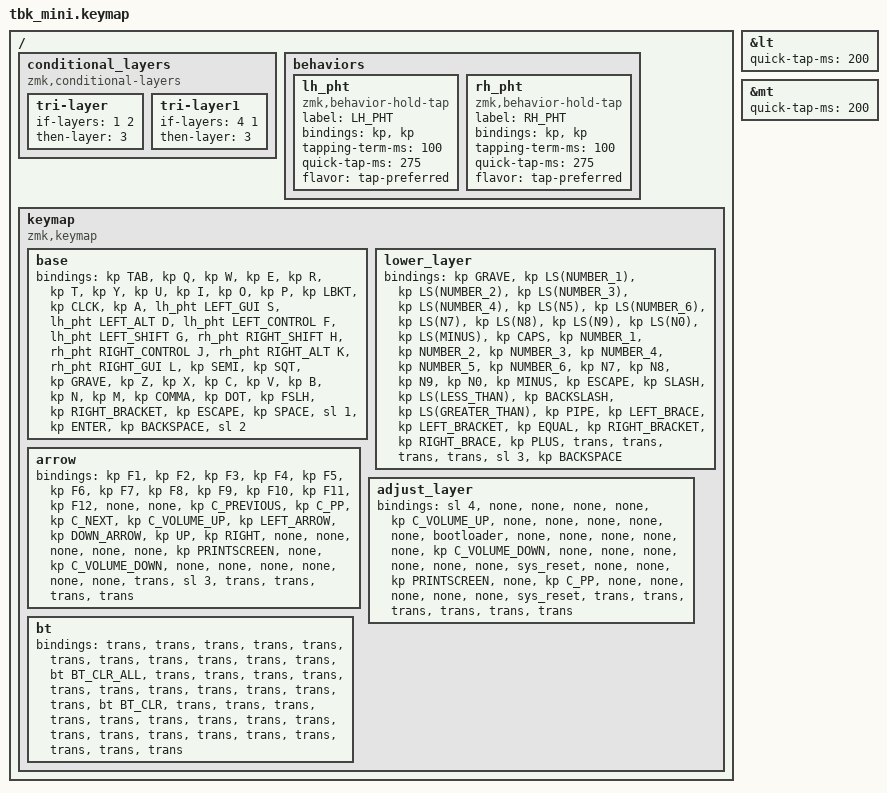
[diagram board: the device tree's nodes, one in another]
/*
 * Copyright (c) 2020 The ZMK Contributors
 *
 * SPDX-License-Identifier: MIT
 */

#include <behaviors.dtsi>
#include <dt-bindings/zmk/bt.h>
#include <dt-bindings/zmk/keys.h>

#define DEF 0
#define LWR 1
#define RSE 2
#define ADJ 3
#define NAV 4

&lt { quick-tap-ms = <200>; };

&mt { quick-tap-ms = <200>; };

/ {
    conditional_layers {
        compatible = "zmk,conditional-layers";

        tri-layer {
            if-layers = <1 2>;
            then-layer = <3>;
        };

        tri-layer1 {
            if-layers = <4 1>;
            then-layer = <3>;
        };
    };

    behaviors {
        lh_pht: lh_pht {
            compatible = "zmk,behavior-hold-tap";
            label = "LH_PHT";
            bindings = <&kp>, <&kp>;

            #binding-cells = <2>;
            tapping-term-ms = <100>;
            quick-tap-ms = <275>;
            flavor = "tap-preferred";
        };

        rh_pht: rh_pht {
            compatible = "zmk,behavior-hold-tap";
            label = "RH_PHT";
            bindings = <&kp>, <&kp>;

            #binding-cells = <2>;
            tapping-term-ms = <100>;
            quick-tap-ms = <275>;
            flavor = "tap-preferred";
        };
    };

    keymap {
        compatible = "zmk,keymap";

        base {
            bindings = <
&kp TAB  &kp Q  &kp W  &kp E  &kp R  &kp T  &kp Y  &kp U  &kp I  &kp O  &kp P  &kp LBKT  &kp CLCK  &kp A  &lh_pht LEFT_GUI S  &lh_pht LEFT_ALT D  &lh_pht LEFT_CONTROL F  &lh_pht LEFT_SHIFT G  &rh_pht RIGHT_SHIFT H  &rh_pht RIGHT_CONTROL J  &rh_pht RIGHT_ALT K  &rh_pht RIGHT_GUI L  &kp SEMI  &kp SQT  &kp GRAVE  &kp Z  &kp X  &kp C  &kp V  &kp B  &kp N  &kp M  &kp COMMA  &kp DOT  &kp FSLH  &kp RIGHT_BRACKET  &kp ESCAPE  &kp SPACE  &sl 1  &kp ENTER  &kp BACKSPACE  &sl 2
            >;
        };

        lower_layer {
            bindings = <
&kp GRAVE  &kp LS(NUMBER_1)  &kp LS(NUMBER_2)  &kp LS(NUMBER_3)  &kp LS(NUMBER_4)  &kp LS(N5)  &kp LS(NUMBER_6)  &kp LS(N7)  &kp LS(N8)  &kp LS(N9)  &kp LS(N0)  &kp LS(MINUS)  &kp CAPS  &kp NUMBER_1  &kp NUMBER_2  &kp NUMBER_3  &kp NUMBER_4  &kp NUMBER_5  &kp NUMBER_6  &kp N7  &kp N8  &kp N9  &kp N0  &kp MINUS  &kp ESCAPE  &kp SLASH  &kp LS(LESS_THAN)  &kp BACKSLASH  &kp LS(GREATER_THAN)  &kp PIPE  &kp LEFT_BRACE  &kp LEFT_BRACKET  &kp EQUAL  &kp RIGHT_BRACKET  &kp RIGHT_BRACE  &kp PLUS  &trans  &trans  &trans  &trans  &sl 3  &kp BACKSPACE
            >;
        };

        arrow {
            bindings = <
&kp F1  &kp F2  &kp F3  &kp F4  &kp F5  &kp F6  &kp F7  &kp F8  &kp F9  &kp F10  &kp F11  &kp F12  &none  &none  &kp C_PREVIOUS  &kp C_PP  &kp C_NEXT  &kp C_VOLUME_UP  &kp LEFT_ARROW  &kp DOWN_ARROW  &kp UP  &kp RIGHT  &none  &none  &none  &none  &none  &kp PRINTSCREEN  &none  &kp C_VOLUME_DOWN  &none  &none  &none  &none  &none  &none  &trans  &sl 3  &trans  &trans  &trans  &trans
            >;
        };

        adjust_layer {
            bindings = <
&sl 4  &none  &none  &none  &none  &kp C_VOLUME_UP  &none  &none  &none  &none  &none  &bootloader  &none  &none  &none  &none  &none  &kp C_VOLUME_DOWN  &none  &none  &none  &none  &none  &none  &sys_reset  &none  &none  &kp PRINTSCREEN  &none  &kp C_PP  &none  &none  &none  &none  &none  &sys_reset  &trans  &trans  &trans  &trans  &trans  &trans
            >;
        };

        bt {
            bindings = <
&trans  &trans  &trans  &trans  &trans  &trans  &trans  &trans  &trans  &trans  &trans  &bt BT_CLR_ALL  &trans  &trans  &trans  &trans  &trans  &trans  &trans  &trans  &trans  &trans  &trans  &bt BT_CLR  &trans  &trans  &trans  &trans  &trans  &trans  &trans  &trans  &trans  &trans  &trans  &trans  &trans  &trans  &trans  &trans  &trans  &trans
            >;
        };
    };
};
